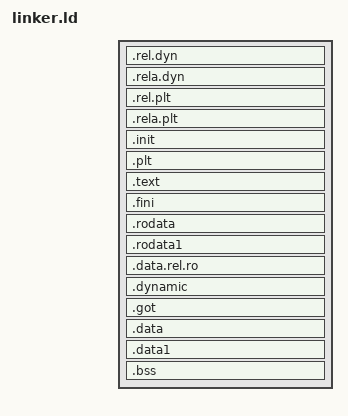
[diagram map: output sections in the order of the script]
/* Script for -z combreloc: combine and sort reloc sections */
OUTPUT_FORMAT("elf32-littlearm", "elf32-bigarm",
	      "elf32-littlearm")
OUTPUT_ARCH(arm)
ENTRY(_start)

SECTIONS
{
  /* Read-only sections, merged into text segment: */
  PROVIDE (__executable_start = SEGMENT_START("text-segment", 0x0)); . = SEGMENT_START("text-segment", 0x0);
  /*.hash           : { *(.hash) }
  .dynsym         : { *(.dynsym) }
  .dynstr         : { *(.dynstr) }*/
  .rel.dyn	:
    {
      *(.rel.init)
      *(.rel.text .rel.text.* .rel.gnu.linkonce.t.*)
      *(.rel.fini)
      *(.rel.rodata .rel.rodata.* .rel.gnu.linkonce.r.*)
      *(.rel.data.rel.ro* .rel.gnu.linkonce.d.rel.ro.*)
      *(.rel.data .rel.data.* .rel.gnu.linkonce.d.*)
      *(.rel.got)
      *(.rel.bss .rel.bss.* .rel.gnu.linkonce.b.*)
    }
  .rela.dyn       :
    {
      *(.rela.init)
      *(.rela.text .rela.text.* .rela.gnu.linkonce.t.*)
      *(.rela.fini)
      *(.rela.rodata .rela.rodata.* .rela.gnu.linkonce.r.*)
      *(.rela.data .rela.data.* .rela.gnu.linkonce.d.*)
      *(.rela.got)
    }
  .rel.plt        :
    {
      *(.rel.plt)
    }
  .rela.plt       :
    {
      *(.rela.plt)
    }
  .init           :
  {
    KEEP (*(.init))
  } =0
  .plt            : { *(.plt) }
  .text           :
  {
    /*__text_start = . ;*/
    *(.text.unlikely .text.*_unlikely)
    *(.text.exit .text.exit.*)
    *(.text.startup .text.startup.*)
    *(.text.hot .text.hot.*)
    *(.text .stub .text.* .gnu.linkonce.t.*)
  } =0
  .fini           :
  {
    KEEP (*(.fini))
  } =0

  .rodata         : { *(.rodata .rodata.* .gnu.linkonce.r.*) }
  .rodata1        : { *(.rodata1) }
  /* Adjust the address for the data segment.  We want to adjust up to
     the same address within the page on the next page up.  */
  . = ALIGN(CONSTANT (MAXPAGESIZE)) + (. & (CONSTANT (MAXPAGESIZE) - 1));

  .data.rel.ro : { *(.data.rel.ro.local* .gnu.linkonce.d.rel.ro.local.*) *(.data.rel.ro* .gnu.linkonce.d.rel.ro.*) }
  .dynamic        : { *(.dynamic) }
  .got            : { *(.got.plt) *(.igot.plt) *(.got) *(.igot) }
  .data           :
  {
    /* __data_start = . ;*/
    *(.data .data.* .gnu.linkonce.d.*)
    SORT(CONSTRUCTORS)
  }
  .data1          : { *(.data1) }
  .bss            :
  {
   *(.dynbss)
   *(.bss .bss.* .gnu.linkonce.b.*)
   *(COMMON)
  }

  /DISCARD/ : 
  {
    *(.note.GNU-stack) *(.gnu_debuglink) *(.gnu.lto_*) *(.gnu*) *(.note*) *(.stab*) *(.comment*)
    *( *)
  }
}



